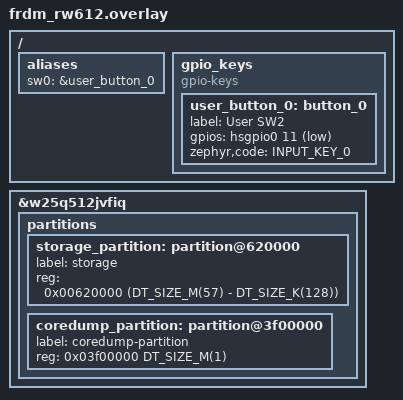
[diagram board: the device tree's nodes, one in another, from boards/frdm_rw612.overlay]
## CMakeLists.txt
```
cmake_minimum_required(VERSION 3.20.0)

if(EXISTS "${CMAKE_CURRENT_SOURCE_DIR}/credentials.conf")
    list(APPEND EXTRA_CONF_FILE "${CMAKE_CURRENT_SOURCE_DIR}/credentials.conf")
endif()

find_package(Zephyr REQUIRED HINTS $ENV{ZEPHYR_BASE})
project(spotflow_showcase)

# Automatic main-firmware handling requires MCUboot via sysbuild.
test_sysbuild()

add_subdirectory(../net-common ${CMAKE_CURRENT_BINARY_DIR}/net-common)

target_sources(app PRIVATE
    src/button.c
    src/identity.c
    src/main.c
    src/ota.c
    src/telemetry.c
)
```

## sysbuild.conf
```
# Automatic handling of main firmware requires MCUboot.
SB_CONFIG_BOOTLOADER_MCUBOOT=y
```

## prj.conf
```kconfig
# Enable the Spotflow SDK and its MQTT observability features.
CONFIG_SPOTFLOW=y
CONFIG_SPOTFLOW_LOG_BACKEND=y
CONFIG_SPOTFLOW_COREDUMPS=y
CONFIG_SPOTFLOW_METRICS=y
CONFIG_SPOTFLOW_METRICS_HEARTBEAT=y
CONFIG_SPOTFLOW_METRICS_SYSTEM=y
CONFIG_SPOTFLOW_SESSION_METADATA_BUFFER_SIZE=512

# Track only the sample's main thread to demonstrate the selective stack API.
CONFIG_SPOTFLOW_METRICS_SYSTEM_STACK_ALL_THREADS=n
CONFIG_SPOTFLOW_METRICS_SYSTEM_STACK_MAX_THREADS=4

# Enable automatic main-firmware OTA and delegated artifact handling.
CONFIG_SPOTFLOW_OTA=y
CONFIG_SPOTFLOW_OTA_AUTO_HANDLE_MAIN_FIRMWARE=y

# Zephyr logging and coredump contents.
CONFIG_LOG=y
CONFIG_LOG_MAX_LEVEL=4
CONFIG_LOG_RUNTIME_FILTERING=y
CONFIG_REQUIRES_FLOAT_PRINTF=y
CONFIG_DEBUG_COREDUMP_THREADS_METADATA=y
CONFIG_DEBUG_COREDUMP_MEMORY_DUMP_THREADS=y

# The sample button distinguishes short and long presses.
CONFIG_GPIO=y

# Networking requirements shared with the other MQTT samples.
CONFIG_NETWORKING=y
CONFIG_NET_MGMT=y
CONFIG_NET_MGMT_EVENT=y
CONFIG_NET_MGMT_EVENT_INFO=y
CONFIG_NET_CONFIG_AUTO_INIT=n
CONFIG_NET_CONNECTION_MANAGER=y
CONFIG_NET_DHCPV4=y
CONFIG_NET_IPV4=y
CONFIG_NET_IPV6=n
CONFIG_NET_TCP=y
CONFIG_NET_UDP=y

# Persist cloud configuration and OTA state and support MCUboot image writes.
CONFIG_FLASH=y
CONFIG_FLASH_MAP=y
CONFIG_NVS=y
CONFIG_SETTINGS=y
CONFIG_SETTINGS_NVS=y
CONFIG_STREAM_FLASH=y

CONFIG_MAIN_STACK_SIZE=4096
CONFIG_SPOTFLOW_MODULE_DEFAULT_LOG_LEVEL=3
CONFIG_SPOTFLOW_OTA_LOG_LEVEL=4

# This permits development boards without a hardware RNG to connect. Remove it
# in production and use a suitable entropy source instead.
CONFIG_MBEDTLS_PSA_CRYPTO_LEGACY_RNG=y
```

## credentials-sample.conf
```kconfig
# Copy this file to credentials.conf and fill in the values.
CONFIG_NET_WIFI_SSID=""
CONFIG_NET_WIFI_PASSWORD=""
CONFIG_SPOTFLOW_INGEST_KEY="your-ingest-key"

# The sample normally derives a stable runtime ID from Zephyr's hardware-info
# API. This value is used as a fallback when hardware ID retrieval fails.
CONFIG_SPOTFLOW_DEVICE_ID="your-device-id"
```

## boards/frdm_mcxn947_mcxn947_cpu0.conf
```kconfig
CONFIG_NET_BUF_DATA_SIZE=256
```

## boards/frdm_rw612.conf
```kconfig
# Fix the Wi-Fi buffer size on Zephyr 4.1 and later.
CONFIG_NET_BUF_DATA_SIZE=256
CONFIG_NXP_WIFI_SOFTAP_SUPPORT=n
```

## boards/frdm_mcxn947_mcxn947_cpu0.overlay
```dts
/* Reserve the final MiB of external flash for coredumps. */
&w25q64jvssiq {
	partitions {
		storage_partition: partition@0 {
			label = "storage";
			reg = <0x0 0x100000>;
		};

		coredump_partition: partition@700000 {
			label = "coredump-partition";
			reg = <0x700000 0x100000>;
		};
	};
};
```

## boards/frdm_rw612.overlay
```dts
/* Add the button definition missing from older Zephyr versions. */
#include <zephyr/dt-bindings/input/input-event-codes.h>

/ {
	aliases {
		sw0 = &user_button_0;
	};

	gpio_keys {
		compatible = "gpio-keys";
		user_button_0: button_0 {
			label = "User SW2";
			gpios = <&hsgpio0 11 (GPIO_ACTIVE_LOW | GPIO_PULL_UP)>;
			zephyr,code = <INPUT_KEY_0>;
			status = "okay";
		};
	};
};

/* Reserve the final MiB of external flash for coredumps. */
&w25q512jvfiq {
	partitions {
		storage_partition: partition@620000 {
			label = "storage";
			reg = <0x00620000 (DT_SIZE_M(57) - DT_SIZE_K(128))>;
		};

		coredump_partition: partition@3f00000 {
			label = "coredump-partition";
			reg = <0x03f00000 DT_SIZE_M(1)>;
		};
	};
};
```

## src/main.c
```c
#include "showcase.h"

#include "net.h"

#include <zephyr/logging/log.h>

LOG_MODULE_REGISTER(showcase, LOG_LEVEL_INF);

#define TELEMETRY_INTERVAL K_SECONDS(5)

int main(void)
{
	LOG_INF("Starting the Spotflow API showcase");

	int rc = showcase_button_init();

	if (rc < 0) {
		return rc;
	}
	rc = showcase_ota_init();
	if (rc < 0) {
		LOG_ERR("Failed to initialize the OTA showcase: %d", rc);
		return rc;
	}
	rc = showcase_telemetry_init();
	if (rc < 0) {
		LOG_ERR("Failed to initialize telemetry: %d", rc);
		return rc;
	}

	/* Allow network devices to complete their own initialization first. */
	k_sleep(K_SECONDS(1));
	spotflow_sample_net_init();

	while (true) {
		enum showcase_button_action action;

		rc = showcase_button_get_action(&action, TELEMETRY_INTERVAL);
		if (rc == -EAGAIN) {
			showcase_telemetry_emit();
			continue;
		}
		if (rc < 0) {
			LOG_ERR("Failed to receive a button action: %d", rc);
			continue;
		}

		if (action == SHOWCASE_BUTTON_SHORT_PRESS) {
			showcase_ota_handle_short_press();
		} else if (!showcase_ota_handle_long_press()) {
			LOG_ERR("No OTA update is active; creating a coredump");
			k_sleep(K_MSEC(100));
			k_oops();
		}
	}

	return 0;
}
```

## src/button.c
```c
#include "showcase.h"

#include <zephyr/drivers/gpio.h>
#include <zephyr/logging/log.h>

LOG_MODULE_REGISTER(showcase_button, LOG_LEVEL_INF);

#define SW0_NODE DT_ALIAS(sw0)
#define LONG_PRESS_DURATION K_SECONDS(3)

#if !DT_NODE_HAS_STATUS_OKAY(SW0_NODE)
#error "Unsupported board: sw0 devicetree alias is not defined"
#endif

static const struct gpio_dt_spec button = GPIO_DT_SPEC_GET(SW0_NODE, gpios);
static struct gpio_callback button_callback_data;
static struct k_work_delayable long_press_work;
static atomic_t button_down;
static atomic_t long_press_reported;

K_MSGQ_DEFINE(button_actions, sizeof(enum showcase_button_action), 4, 1);

static void queue_action(enum showcase_button_action action)
{
	if (k_msgq_put(&button_actions, &action, K_NO_WAIT) < 0) {
		LOG_WRN("Dropping button action because the queue is full");
	}
}

static void long_press_work_handler(struct k_work* work)
{
	ARG_UNUSED(work);

	if (atomic_get(&button_down) && atomic_cas(&long_press_reported, 0, 1)) {
		queue_action(SHOWCASE_BUTTON_LONG_PRESS);
	}
}

static void button_changed(const struct device* dev, struct gpio_callback* cb, uint32_t pins)
{
	ARG_UNUSED(dev);
	ARG_UNUSED(cb);
	ARG_UNUSED(pins);

	int pressed = gpio_pin_get_dt(&button);

	if (pressed > 0 && atomic_cas(&button_down, 0, 1)) {
		atomic_clear(&long_press_reported);
		(void)k_work_reschedule(&long_press_work, LONG_PRESS_DURATION);
	} else if (pressed == 0 && atomic_cas(&button_down, 1, 0)) {
		(void)k_work_cancel_delayable(&long_press_work);
		if (!atomic_get(&long_press_reported)) {
			queue_action(SHOWCASE_BUTTON_SHORT_PRESS);
		}
	}
}

int showcase_button_init(void)
{
	if (!gpio_is_ready_dt(&button)) {
		LOG_ERR("Button device %s is not ready", button.port->name);
		return -ENODEV;
	}

	int rc = gpio_pin_configure_dt(&button, GPIO_INPUT);

	if (rc < 0) {
		LOG_ERR("Failed to configure the button: %d", rc);
		return rc;
	}

	k_work_init_delayable(&long_press_work, long_press_work_handler);
	gpio_init_callback(&button_callback_data, button_changed, BIT(button.pin));

	rc = gpio_add_callback(button.port, &button_callback_data);
	if (rc < 0) {
		LOG_ERR("Failed to add the button callback: %d", rc);
		return rc;
	}

	rc = gpio_pin_interrupt_configure_dt(&button, GPIO_INT_EDGE_BOTH);
	if (rc < 0) {
		LOG_ERR("Failed to enable button interrupts: %d", rc);
		return rc;
	}

	LOG_INF("Short press: confirm an unconfirmed OTA image");
	LOG_INF("Long press: abort active OTA, otherwise create a coredump");
	return 0;
}

int showcase_button_get_action(enum showcase_button_action* action, k_timeout_t timeout)
{
	if (action == NULL) {
		return -EINVAL;
	}

	return k_msgq_get(&button_actions, action, timeout);
}
```

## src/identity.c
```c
#include <spotflow/session_metadata.h>

#include <zephyr/drivers/hwinfo.h>
#include <zephyr/sys/util.h>

#include <stdio.h>

#define HARDWARE_ID_MAX_SIZE 16

static char runtime_device_id[sizeof("showcase-") + (2 * HARDWARE_ID_MAX_SIZE)];

const char* spotflow_override_device_id(void)
{
	uint8_t hardware_id[HARDWARE_ID_MAX_SIZE];
	ssize_t hardware_id_size = hwinfo_get_device_id(hardware_id, ARRAY_SIZE(hardware_id));

	if (hardware_id_size <= 0) {
		return NULL;
	}

	(void)snprintf(runtime_device_id, sizeof(runtime_device_id), "showcase-");
	for (size_t i = 0; i < (size_t)hardware_id_size; ++i) {
		size_t offset = sizeof("showcase-") - 1 + (2 * i);

		(void)snprintf(&runtime_device_id[offset], sizeof(runtime_device_id) - offset,
			       "%02X", hardware_id[i]);
	}

	return runtime_device_id;
}

static const struct spotflow_session_label session_labels[] = {
	{
		.key = "sample",
		.type = SPOTFLOW_SESSION_LABEL_STRING,
		.value.string = "showcase",
	},
	{
		.key = "hardwareRevision",
		.type = SPOTFLOW_SESSION_LABEL_INT,
		.value.integer = 1,
	},
	{
		.key = "samplingRatio",
		.type = SPOTFLOW_SESSION_LABEL_FLOAT,
		.value.floating = 0.25,
	},
	{
		.key = "diagnosticsEnabled",
		.type = SPOTFLOW_SESSION_LABEL_BOOL,
		.value.boolean = true,
	},
};

struct spotflow_session_metadata_labels spotflow_override_session_metadata_labels(void)
{
	return (struct spotflow_session_metadata_labels){
		.items = session_labels,
		.count = ARRAY_SIZE(session_labels),
	};
}
```

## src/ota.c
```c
#include "showcase.h"

#include <spotflow/ota.h>

#include <zephyr/logging/log.h>
#include <zephyr/sys/reboot.h>

LOG_MODULE_REGISTER(showcase_ota, LOG_LEVEL_INF);

#define DELEGATED_PAUSE_AFTER_BYTES 4096
#define DEMO_PAUSE_DURATION K_SECONDS(3)

static SPOTFLOW_DEFINE_DOWNLOADER(delegated_downloader);

struct delegated_download_context {
	size_t received;
	uint32_t checksum;
	bool valid;
	bool saw_last;
	bool pause_demonstrated;
};

static struct k_work_delayable resume_main_work;
static struct k_work_delayable resume_delegated_work;
static atomic_t main_pause_demonstrated;
static atomic_t delegated_update_active;

static const char* ota_phase_name(enum spotflow_ota_phase phase)
{
	switch (phase) {
	case SPOTFLOW_OTA_PHASE_NOT_RUNNING:
		return "NOT_RUNNING";
	case SPOTFLOW_OTA_PHASE_PENDING_DOWNLOAD:
		return "PENDING_DOWNLOAD";
	case SPOTFLOW_OTA_PHASE_DOWNLOADING:
		return "DOWNLOADING";
	case SPOTFLOW_OTA_PHASE_PENDING_UPGRADE:
		return "PENDING_UPGRADE";
	case SPOTFLOW_OTA_PHASE_PENDING_REBOOT:
		return "PENDING_REBOOT";
	case SPOTFLOW_OTA_PHASE_UNCONFIRMED:
		return "UNCONFIRMED";
	default:
		return "UNKNOWN";
	}
}

static void resume_main_work_handler(struct k_work* work)
{
	ARG_UNUSED(work);

	struct spotflow_ota_main_firmware_state state;
	int rc = spotflow_resume_main_firmware_update(&state);

	if (rc < 0) {
		LOG_WRN("Automatic main-firmware resume was not applicable: %d", rc);
		return;
	}

	LOG_INF("Resumed main-firmware update in phase %s", ota_phase_name(state.phase));
}

static void resume_delegated_work_handler(struct k_work* work)
{
	ARG_UNUSED(work);

	int rc = spotflow_resume_download(&delegated_downloader);

	if (rc < 0) {
		LOG_WRN("Delegated download resume was not applicable: %d", rc);
	} else {
		LOG_INF("Resumed delegated artifact download");
	}
}

static void receive_delegated_block(const struct spotflow_artifact_block* block,
				    struct spotflow_downloader* downloader, void* callback_ctx)
{
	struct delegated_download_context* context = callback_ctx;

	if (block->offset != context->received) {
		context->valid = false;
		(void)spotflow_cancel_download(downloader);
		return;
	}

	for (size_t i = 0; i < block->data_len; ++i) {
		context->checksum = (context->checksum * 16777619U) ^ block->data[i];
	}
	context->received += block->data_len;
	context->saw_last = block->is_last;

	if (!context->pause_demonstrated && context->received >= DELEGATED_PAUSE_AFTER_BYTES &&
	    !block->is_last) {
		int rc = spotflow_pause_download(downloader);

		if (rc == 0) {
			context->pause_demonstrated = true;
			LOG_INF("Paused delegated download after %zu bytes", context->received);
			(void)k_work_reschedule(&resume_delegated_work, DEMO_PAUSE_DURATION);
		}
	}
}

void spotflow_on_main_firmware_update_progressed(
	const struct spotflow_ota_main_firmware_state* state)
{
	if (state == NULL) {
		return;
	}

	LOG_INF("Main firmware: phase=%s paused=%d result=%d", ota_phase_name(state->phase),
		state->is_paused, state->result);

	if (state->phase == SPOTFLOW_OTA_PHASE_NOT_RUNNING) {
		atomic_clear(&main_pause_demonstrated);
		return;
	}

	if (state->phase != SPOTFLOW_OTA_PHASE_PENDING_DOWNLOAD || state->is_paused ||
	    !atomic_cas(&main_pause_demonstrated, 0, 1)) {
		return;
	}

	struct spotflow_firmware_info info;
	struct spotflow_download_request request;
	int rc = spotflow_get_main_firmware_update_info(&info, &request);

	if (rc == 0) {
		LOG_INF("Main artifact '%s' version '%s' is ready", info.slug, info.version);
	}

	struct spotflow_ota_main_firmware_state paused_state;

	rc = spotflow_pause_main_firmware_update(&paused_state);
	if (rc < 0) {
		LOG_WRN("Failed to demonstrate main-firmware pause: %d", rc);
		return;
	}

	LOG_INF("Paused main-firmware update for three seconds");
	(void)k_work_reschedule(&resume_main_work, DEMO_PAUSE_DURATION);
}

enum spotflow_ota_result
spotflow_on_handle_firmware_update(const struct spotflow_firmware_info* info)
{
	if (info == NULL || info->download_request == NULL) {
		return SPOTFLOW_OTA_RESULT_FAILED;
	}

	LOG_INF("Simulating delegated update for '%s', version '%s'", info->slug, info->version);
	struct delegated_download_context context = {
		.checksum = 2166136261U,
		.valid = true,
	};

	atomic_set(&delegated_update_active, 1);
	int rc = spotflow_download_artifact(&delegated_downloader, info->download_request,
					    receive_delegated_block, &context);
	atomic_clear(&delegated_update_active);

	if (spotflow_is_update_canceled() || rc == -ECANCELED) {
		LOG_INF("Delegated update canceled after %zu bytes", context.received);
		return SPOTFLOW_OTA_RESULT_CANCELED;
	}
	if (rc < 0 || !context.valid || !context.saw_last) {
		LOG_ERR("Delegated download failed: %d", rc);
		return SPOTFLOW_OTA_RESULT_FAILED;
	}

	/* A real product would verify, install, and persist the external firmware here. */
	LOG_INF("Simulated delegated install succeeded: bytes=%zu checksum=%08x", context.received,
		context.checksum);
	return SPOTFLOW_OTA_RESULT_SUCCEEDED;
}

void spotflow_on_update_canceled(void)
{
	if (atomic_get(&delegated_update_active) &&
	    spotflow_get_downloader_state(&delegated_downloader) !=
		    SPOTFLOW_DOWNLOADER_STATE_INACTIVE) {
		(void)spotflow_cancel_download(&delegated_downloader);
	}
}

int showcase_ota_init(void)
{
	k_work_init_delayable(&resume_main_work, resume_main_work_handler);
	k_work_init_delayable(&resume_delegated_work, resume_delegated_work_handler);

	struct spotflow_ota_main_firmware_state state;
	int rc = spotflow_get_main_firmware_update_state(&state);

	if (rc < 0) {
		return rc;
	}

	LOG_INF("Initial main-firmware state: phase=%s result=%d", ota_phase_name(state.phase),
		state.result);
	if (state.phase == SPOTFLOW_OTA_PHASE_UNCONFIRMED) {
		LOG_WRN("Running image is unconfirmed; short-press the button to accept it");
	}

	return 0;
}

void showcase_ota_handle_short_press(void)
{
	struct spotflow_ota_main_firmware_state state;
	int rc = spotflow_get_main_firmware_update_state(&state);

	if (rc < 0) {
		LOG_ERR("Failed to read OTA state: %d", rc);
		return;
	}
	if (state.phase != SPOTFLOW_OTA_PHASE_UNCONFIRMED) {
		LOG_INF("Short press ignored: no unconfirmed main image");
		return;
	}

	rc = spotflow_confirm_main_firmware_image(&state);
	if (rc < 0) {
		LOG_ERR("Failed to confirm the main image: %d", rc);
	} else {
		LOG_INF("Confirmed the running main image");
	}
}

bool showcase_ota_handle_long_press(void)
{
	if (atomic_get(&delegated_update_active)) {
		int rc = spotflow_cancel_download(&delegated_downloader);

		LOG_INF("Long press requested delegated OTA cancellation: %d", rc);
		return true;
	}

	struct spotflow_ota_main_firmware_state state;
	int rc = spotflow_get_main_firmware_update_state(&state);

	if (rc < 0) {
		LOG_ERR("Failed to read OTA state: %d", rc);
		return true;
	}

	switch (state.phase) {
	case SPOTFLOW_OTA_PHASE_NOT_RUNNING:
		return false;
	case SPOTFLOW_OTA_PHASE_PENDING_DOWNLOAD:
	case SPOTFLOW_OTA_PHASE_DOWNLOADING:
	case SPOTFLOW_OTA_PHASE_PENDING_UPGRADE:
		rc = spotflow_abort_main_firmware_update(&state);
		LOG_INF("Long press requested main OTA abort: %d", rc);
		return true;
	case SPOTFLOW_OTA_PHASE_PENDING_REBOOT:
		LOG_WRN("The test upgrade is committed and can no longer be aborted");
		return true;
	case SPOTFLOW_OTA_PHASE_UNCONFIRMED:
		LOG_WRN("Rejecting the unconfirmed image; MCUboot will roll it back");
		k_sleep(K_MSEC(100));
		sys_reboot(SYS_REBOOT_COLD);
		return true;
	default:
		return true;
	}
}
```

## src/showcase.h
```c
#ifndef SPOTFLOW_SHOWCASE_H
#define SPOTFLOW_SHOWCASE_H

#include <stdbool.h>

#include <zephyr/kernel.h>

enum showcase_button_action {
	SHOWCASE_BUTTON_SHORT_PRESS,
	SHOWCASE_BUTTON_LONG_PRESS,
};

int showcase_button_init(void);
int showcase_button_get_action(enum showcase_button_action* action, k_timeout_t timeout);

int showcase_ota_init(void);
void showcase_ota_handle_short_press(void);
bool showcase_ota_handle_long_press(void);

int showcase_telemetry_init(void);
void showcase_telemetry_emit(void);

#endif /* SPOTFLOW_SHOWCASE_H */
```

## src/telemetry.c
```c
#include "showcase.h"

#include "metrics/spotflow_metrics_backend.h"
#include "metrics/system/spotflow_metrics_system_stack.h"

#include <zephyr/logging/log.h>
#include <zephyr/random/random.h>

LOG_MODULE_REGISTER(showcase_telemetry, LOG_LEVEL_DBG);

static struct spotflow_metric_int* cycle_metric;
static struct spotflow_metric_float* temperature_metric;
static struct spotflow_metric_int* fault_metric;
static struct spotflow_metric_float* operation_duration_metric;
static struct spotflow_metric_int* periodic_event_metric;
static int64_t cycle;

int showcase_telemetry_init(void)
{
	int rc = spotflow_register_metric_int("showcase_cycle", SPOTFLOW_AGG_INTERVAL_1MIN,
					      &cycle_metric);

	if (rc < 0) {
		return rc;
	}

	rc = spotflow_register_metric_float("showcase_temperature_celsius",
					    SPOTFLOW_AGG_INTERVAL_NONE, &temperature_metric);
	if (rc < 0) {
		return rc;
	}

	rc = spotflow_register_metric_int_with_labels("showcase_fault", SPOTFLOW_AGG_INTERVAL_NONE,
						      4, 1, &fault_metric);
	if (rc < 0) {
		return rc;
	}

	rc = spotflow_register_metric_float_with_labels("showcase_operation_duration_ms",
							SPOTFLOW_AGG_INTERVAL_1MIN, 4, 2,
							&operation_duration_metric);
	if (rc < 0) {
		return rc;
	}

	rc = spotflow_register_metric_int("showcase_periodic_event", SPOTFLOW_AGG_INTERVAL_NONE,
					  &periodic_event_metric);
	if (rc < 0) {
		return rc;
	}

	rc = spotflow_metrics_system_stack_enable_thread(k_current_get());
	if (rc < 0) {
		LOG_WRN("Failed to enable main-thread stack metrics: %d", rc);
	}

	LOG_INF("Registered integer, float, labeled, event, and system metrics");
	return 0;
}

void showcase_telemetry_emit(void)
{
	static const char* const operations[] = { "read", "write" };
	static const char* const outcomes[] = { "ok", "retry" };
	const char* operation = operations[cycle % ARRAY_SIZE(operations)];
	const char* outcome = outcomes[(cycle / 2) % ARRAY_SIZE(outcomes)];
	struct spotflow_label operation_labels[] = {
		{ .key = "operation", .value = operation },
		{ .key = "outcome", .value = outcome },
	};
	float temperature = 20.0f + ((float)(sys_rand32_get() % 500U) / 100.0f);
	float duration = 10.0f + ((float)(sys_rand32_get() % 1900U) / 10.0f);

	cycle++;
	LOG_DBG("Showcase debug cycle %lld", cycle);
	LOG_INF("Showcase cycle %lld, temperature %.2f C", cycle, (double)temperature);
	if ((cycle % 4) == 0) {
		LOG_WRN("Demonstration warning on cycle %lld", cycle);
	}
	if ((cycle % 10) == 0) {
		LOG_ERR("Demonstration error on cycle %lld", cycle);
	}

	(void)spotflow_report_metric_int(cycle_metric, cycle);
	(void)spotflow_report_metric_float(temperature_metric, temperature);
	(void)spotflow_report_metric_float_with_labels(operation_duration_metric, duration,
						       operation_labels,
						       ARRAY_SIZE(operation_labels));

	if ((cycle % 6) == 0) {
		struct spotflow_label fault_label = { .key = "code", .value = "timeout" };

		(void)spotflow_report_metric_int_with_labels(fault_metric, cycle, &fault_label, 1);
		(void)spotflow_report_event_with_labels(fault_metric, &fault_label, 1);
	}

	if ((cycle % 3) == 0) {
		(void)spotflow_report_event(periodic_event_metric);
	}
}
```
